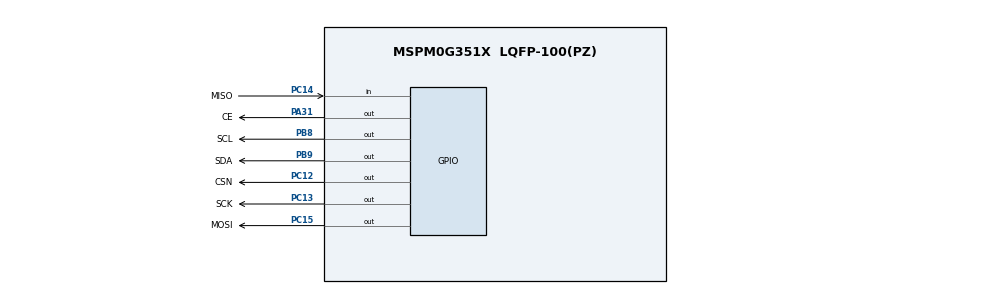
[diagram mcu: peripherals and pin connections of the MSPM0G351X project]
/**
 * @cliArgs --device "MSPM0G351X" --part "Default" --package "LQFP-100(PZ)" --product "mspm0_sdk@2.11.00.07"
 * @versions {"tool":"1.26.2+4477"}
 */

/**
 * Import the modules used in this configuration.
 */
const GPIO   = scripting.addModule("/ti/driverlib/GPIO", {}, false);
const GPIO1  = GPIO.addInstance();
const GPIO2  = GPIO.addInstance();
const SYSCTL = scripting.addModule("/ti/driverlib/SYSCTL");

/**
 * Write custom configuration values to the imported modules.
 */
const divider9       = system.clockTree["UDIV"];
divider9.divideValue = 2;

const multiplier2         = system.clockTree["PLL_QDIV"];
multiplier2.multiplyValue = 4;

const mux4       = system.clockTree["EXHFMUX"];
mux4.inputSelect = "EXHFMUX_XTAL";

const mux8       = system.clockTree["HSCLKMUX"];
mux8.inputSelect = "HSCLKMUX_SYSPLL0";

const mux12       = system.clockTree["SYSPLLMUX"];
mux12.inputSelect = "zSYSPLLMUX_HFCLK";

const pinFunction4     = system.clockTree["HFXT"];
pinFunction4.inputFreq = 40;
pinFunction4.enable    = true;

GPIO1.$name                         = "OLED";
GPIO1.associatedPins.create(2);
GPIO1.associatedPins[0].$name       = "SCL";
GPIO1.associatedPins[0].pin.$assign = "PB8";
GPIO1.associatedPins[1].$name       = "SDA";
GPIO1.associatedPins[1].pin.$assign = "PB9";

const Board = scripting.addModule("/ti/driverlib/Board", {}, false);

GPIO2.$name                         = "NRF";
GPIO2.associatedPins.create(5);
GPIO2.associatedPins[0].$name       = "CE";
GPIO2.associatedPins[0].pin.$assign = "PA31";
GPIO2.associatedPins[1].$name       = "CSN";
GPIO2.associatedPins[1].pin.$assign = "PC12";
GPIO2.associatedPins[2].$name       = "SCK";
GPIO2.associatedPins[2].pin.$assign = "PC13";
GPIO2.associatedPins[3].$name       = "MOSI";
GPIO2.associatedPins[3].pin.$assign = "PC15";
GPIO2.associatedPins[4].$name       = "MISO";
GPIO2.associatedPins[4].direction   = "INPUT";
GPIO2.associatedPins[4].pin.$assign = "PC14";

SYSCTL.forceDefaultClkConfig = true;
SYSCTL.clockTreeEn           = true;

/**
 * Pinmux solution for unlocked pins/peripherals. This ensures that minor changes to the automatic solver in a future
 * version of the tool will not impact the pinmux you originally saw.  These lines can be completely deleted in order to
 * re-solve from scratch.
 */
pinFunction4.peripheral.$suggestSolution           = "SYSCTL";
pinFunction4.peripheral.hfxInPin.$suggestSolution  = "PA5";
pinFunction4.peripheral.hfxOutPin.$suggestSolution = "PA6";
Board.peripheral.$suggestSolution                  = "DEBUGSS";
Board.peripheral.swclkPin.$suggestSolution         = "PA20";
Board.peripheral.swdioPin.$suggestSolution         = "PA19";
